# ATmega16 register map
Vendor: Atmel; File version: 1.0
CPU: other r0p0, little endian, no MPU, no FPU, 4 interrupt priority bits
Registers are 8-bit, read-write, reset 0x0 unless marked. A register's access mark holds for its fields unless they carry their own. Offsets are from the block's base; [hi:lo] are bit positions; {n}, {i} and the like mark numbered series; 'fields as' and 'values as' point back to an identical list.

## CPU — CPU Registers
Base 0x00800050
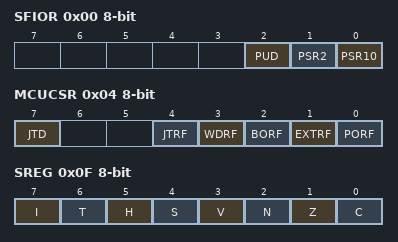
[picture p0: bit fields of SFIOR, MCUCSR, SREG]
0x00 SFIOR — Special function I/O register
  [2] PUD — Pull-up Disable
  [1] PSR2 — Prescaler reset
  [0] PSR10 — Prescaler reset
0x01 OSCCAL — Oscillator Calibration Value
  [7:0] OSCCAL — Oscillator Calibration
0x04 MCUCSR — MCU Control And Status Register
  [7] JTD — JTAG Interface Disable
  [4] JTRF — JTAG Reset Flag
  [3] WDRF — Watchdog Reset Flag
  [2] BORF — Brown-out Reset Flag
  [1] EXTRF — External Reset Flag
  [0] PORF — Power-on reset flag
0x05 MCUCR — MCU Control Register
  [6] SE — Sleep Enable
  [7:4] SM — Sleep Mode Select
    0=IDLE; 1=ADC (ADC Noise Reduction (If Available)); 2=PDOWN (Power Down); 3=PSAVE (Power Save); 10=STDBY (Standby); 11=ESTDBY (Extended Standby)
  [3:2] ISC1 — Interrupt Sense Control 1 Bits
    0=LOW_LEVEL_OF_INTX; 1=ANY_LOGICAL_CHANGE_IN_INTX; 2=FALLING_EDGE_OF_INTX; 3=RISING_EDGE_OF_INTX
  [1:0] ISC0 — Interrupt Sense Control 0 Bits
    values as ISC1
0x0D SP 16-bit (reset mask 0xFF) — Stack Pointer
0x0F SREG — Status Register
  [7] I — Global Interrupt Enable
  [6] T — Bit Copy Storage
  [5] H — Half Carry Flag
  [4] S — Sign Bit
  [3] V — Two's Complement Overflow Flag
  [2] N — Negative Flag
  [1] Z — Zero Flag
  [0] C — Carry Flag

## EEPROM
Base 0x0080003C
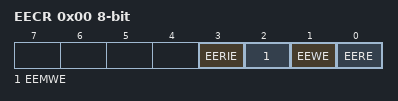
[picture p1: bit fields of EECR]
0x00 EECR — EEPROM Control Register
  [3] EERIE — EEPROM Ready Interrupt Enable
  [2] EEMWE — EEPROM Master Write Enable
  [1] EEWE — EEPROM Write Enable
  [0] EERE — EEPROM Read Enable
0x01 EEDR — EEPROM Data Register
0x02 EEAR 16-bit (reset mask 0xFF) — EEPROM Address Register Bytes

## EXINT — External Interrupts
Base 0x00800054
0x00 MCUCSR — MCU Control And Status Register
  [6] ISC2 — Interrupt Sense Control 2
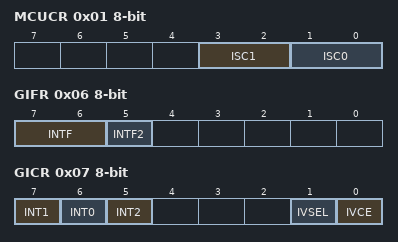
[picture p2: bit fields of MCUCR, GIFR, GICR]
0x01 MCUCR — General Interrupt Control Register
  [3:2] ISC1 — Interrupt Sense Control 1 Bits
    0=LOW_LEVEL_OF_INTX; 1=ANY_LOGICAL_CHANGE_OF_INTX; 2=FALLING_EDGE_OF_INTX; 3=RISING_EDGE_OF_INTX
  [1:0] ISC0 — Interrupt Sense Control 0 Bits
    values as ISC1
0x06 GIFR — General Interrupt Flag Register (read-only for debugger)
  [7:6] INTF — External Interrupt Flags
  [5] INTF2 — External Interrupt Flag 2
0x07 GICR — General Interrupt Control Register
  [7] INT1 — External Interrupt Request 1 Enable
  [6] INT0 — External Interrupt Request 0 Enable
  [5] INT2 — External Interrupt Request 2 Enable
  [1] IVSEL — Interrupt Vector Select
  [0] IVCE — Interrupt Vector Change Enable

## JTAG — JTAG Interface
Base 0x00800051
0x00 OCDR — On-Chip Debug Related Register in I/O Memory (write-only for debugger)
  [7:0] OCDR — On-Chip Debug Register Bits
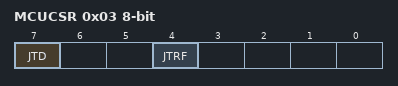
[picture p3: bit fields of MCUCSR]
0x03 MCUCSR — MCU Control And Status Register
  [7] JTD — JTAG Interface Disable
  [4] JTRF — JTAG Reset Flag

## PORTA — I/O Port
Base 0x00800039
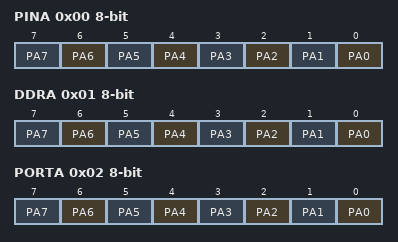
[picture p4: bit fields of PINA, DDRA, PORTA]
0x00 PINA — Port A Input Pins (read-only for debugger)
  [n] PA{n} (n=0..7) — Pin A{n}
0x01 DDRA — Port A Data Direction Register
  [n] PA{n} (n=0..7) — Pin A{n}
0x02 PORTA — Port A Data Register
  [n] PA{n} (n=0..7) — Pin A{n}

## PORTB — I/O Port
Base 0x00800036
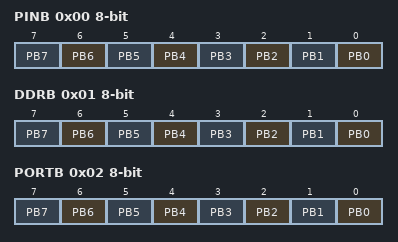
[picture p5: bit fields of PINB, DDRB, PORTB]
0x00 PINB — Port B Input Pins (read-only for debugger)
  [n] PB{n} (n=0..7) — Pin B{n}
0x01 DDRB — Port B Data Direction Register
  [n] PB{n} (n=0..7) — Pin B{n}
0x02 PORTB — Port B Data Register
  [n] PB{n} (n=0..7) — Pin B{n}

## PORTC — I/O Port
Base 0x00800033
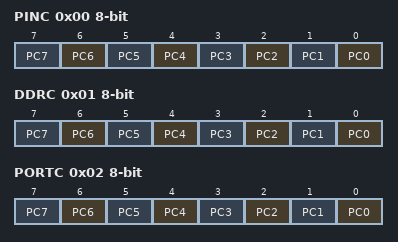
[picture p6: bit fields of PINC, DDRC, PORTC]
0x00 PINC — Port C Input Pins (read-only for debugger)
  [n] PC{n} (n=0..7) — Pin C{n}
0x01 DDRC — Port C Data Direction Register
  [n] PC{n} (n=0..7) — Pin C{n}
0x02 PORTC — Port C Data Register
  [n] PC{n} (n=0..7) — Pin C{n}

## PORTD — I/O Port
Base 0x00800030
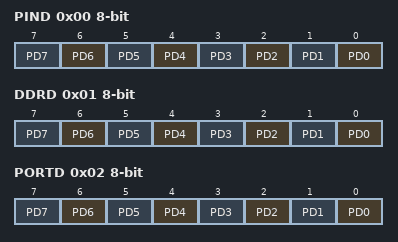
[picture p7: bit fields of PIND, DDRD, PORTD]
0x00 PIND — Port D Input Pins (read-only for debugger)
  [n] PD{n} (n=0..7) — Pin D{n}
0x01 DDRD — Port D Data Direction Register
  [n] PD{n} (n=0..7) — Pin D{n}
0x02 PORTD — Port D Data Register
  [n] PD{n} (n=0..7) — Pin D{n}
